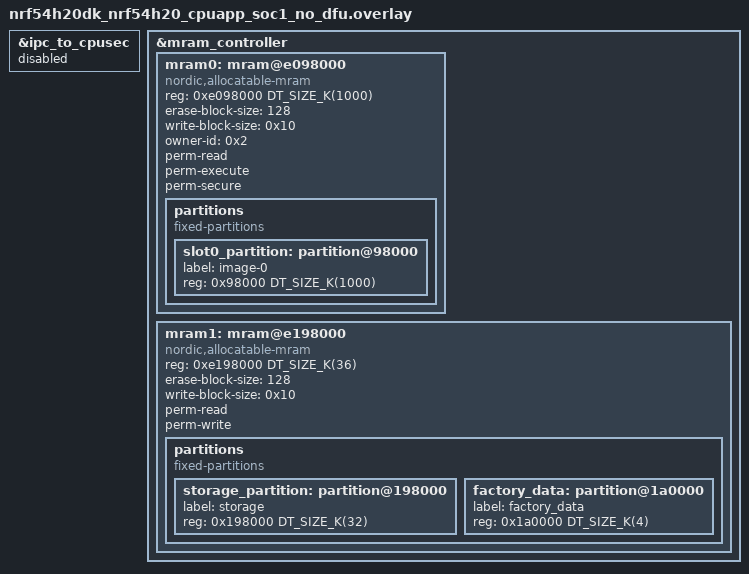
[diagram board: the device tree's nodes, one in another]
/*
 * Copyright (c) 2023 Nordic Semiconductor ASA
 *
 * SPDX-License-Identifier: Apache-2.0
 */

#include <zephyr/dt-bindings/ipc_service/static_vrings.h>
#include <arm/nordic_nrf_next/overlays/entropy_cpuapp.overlay>
#include <arm/nordic_nrf_next/overlays/serial_cpuapp.overlay>
#include "nrf54h20_common.dtsi"

/* Disable communication between the Application and Secure Domains */
&ipc_to_cpusec {
    status = "disabled";
};

/delete-node/ &mram0;
/delete-node/ &mram1;

&mram_controller {
    mram0: mram@e098000 {
        compatible = "nordic,allocatable-mram", "soc-nv-flash";
        reg = <0xe098000 DT_SIZE_K(1000)>;
        #address-cells = <0x1>;
        #size-cells = <0x1>;
        erase-block-size = <128>;
        write-block-size = <0x10>;
        owner-id = <0x2>;
        perm-read;
        perm-execute;
        perm-secure;
        partitions {
            compatible = "fixed-partitions";
            #address-cells = <0x1>;
            #size-cells = <0x1>;
            slot0_partition: partition@98000  {
                label = "image-0";
                reg = <0x98000 DT_SIZE_K(1000)>;
            };
        };
    };

    mram1: mram@e198000 {
        compatible = "nordic,allocatable-mram", "soc-nv-flash";
        reg = <0xe198000 DT_SIZE_K(36)>;
        erase-block-size = <128>;
        write-block-size = <0x10>;
        perm-read;
        perm-write;
        partitions {
            compatible = "fixed-partitions";
            #address-cells = <0x1>;
            #size-cells = <0x1>;
            storage_partition: partition@198000 {
                label = "storage";
                reg = <0x198000 DT_SIZE_K(32)>;
            };
            factory_data: partition@1a0000 {
                label = "factory_data";
                reg = <0x1a0000 DT_SIZE_K(4)>;
            };
        };
    };
};
